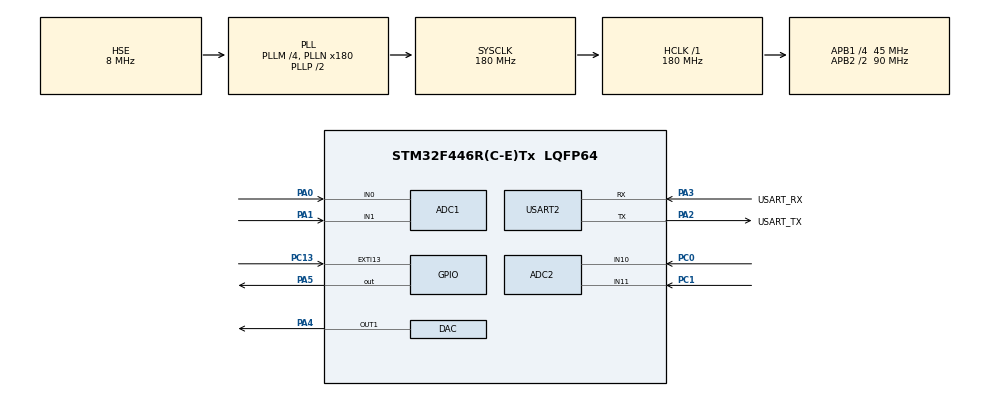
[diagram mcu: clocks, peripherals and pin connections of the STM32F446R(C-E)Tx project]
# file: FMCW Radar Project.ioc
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ADC1.Channel-0\#ChannelRegularConversion=ADC_CHANNEL_0
ADC1.Channel-1\#ChannelRegularConversion=ADC_CHANNEL_1
ADC1.DMAContinuousRequests=ENABLE
ADC1.ExternalTrigConv=ADC_EXTERNALTRIGCONV_T2_TRGO
ADC1.Mode=ADC_DUALMODE_REGSIMULT
ADC1.NbrOfConversion=2
ADC1.NbrOfConversionFlag=1
ADC1.Rank-0\#ChannelRegularConversion=1
ADC1.Rank-1\#ChannelRegularConversion=2
ADC1.SamplingTime-0\#ChannelRegularConversion=ADC_SAMPLETIME_28CYCLES
ADC1.SamplingTime-1\#ChannelRegularConversion=ADC_SAMPLETIME_28CYCLES
ADC1.ScanConvMode=ENABLE
ADC1.master=1
ADC2.Channel-2\#ChannelRegularConversion=ADC_CHANNEL_10
ADC2.Channel-3\#ChannelRegularConversion=ADC_CHANNEL_11
ADC2.DMAAccessMode=ADC_DMAACCESSMODE_2
ADC2.Mode=ADC_DUALMODE_REGSIMULT
ADC2.NbrOfConversion=2
ADC2.NbrOfConversionFlag=1
ADC2.Rank-2\#ChannelRegularConversion=1
ADC2.Rank-3\#ChannelRegularConversion=2
ADC2.SamplingTime-2\#ChannelRegularConversion=ADC_SAMPLETIME_28CYCLES
ADC2.SamplingTime-3\#ChannelRegularConversion=ADC_SAMPLETIME_28CYCLES
ADC2.ScanConvMode=ENABLE
DAC.DAC_Trigger=DAC_TRIGGER_T2_TRGO
Dma.ADC1.1.Direction=DMA_PERIPH_TO_MEMORY
Dma.ADC1.1.FIFOMode=DMA_FIFOMODE_DISABLE
Dma.ADC1.1.Instance=DMA2_Stream0
Dma.ADC1.1.MemDataAlignment=DMA_MDATAALIGN_WORD
Dma.ADC1.1.MemInc=DMA_MINC_ENABLE
Dma.ADC1.1.Mode=DMA_CIRCULAR
Dma.ADC1.1.PeriphDataAlignment=DMA_PDATAALIGN_WORD
Dma.ADC1.1.PeriphInc=DMA_PINC_DISABLE
Dma.ADC1.1.Priority=DMA_PRIORITY_LOW
Dma.DAC1.0.Direction=DMA_MEMORY_TO_PERIPH
Dma.DAC1.0.FIFOMode=DMA_FIFOMODE_DISABLE
Dma.DAC1.0.Instance=DMA1_Stream5
Dma.DAC1.0.MemDataAlignment=DMA_MDATAALIGN_HALFWORD
Dma.DAC1.0.MemInc=DMA_MINC_ENABLE
Dma.DAC1.0.Mode=DMA_CIRCULAR
Dma.DAC1.0.PeriphDataAlignment=DMA_PDATAALIGN_HALFWORD
Dma.DAC1.0.PeriphInc=DMA_PINC_DISABLE
Dma.DAC1.0.Priority=DMA_PRIORITY_LOW
Dma.Request0=DAC1
Dma.Request1=ADC1
IWDG.Prescaler=IWDG_PRESCALER_64
IWDG.Reload=249
Mcu.Family=STM32F4
Mcu.Name=STM32F446R(C-E)Tx
Mcu.Package=LQFP64
NUCLEO-F446RE.BUTTON=1
NUCLEO-F446RE.LD1=true
NVIC.DMA1_Stream5_IRQn=true\:0\:0\:false\:false\:true\:false\:true\:true
NVIC.DMA2_Stream0_IRQn=true\:0\:0\:false\:false\:true\:false\:true\:true
NVIC.EXTI15_10_IRQn=true\:0\:0\:false\:false\:true\:false\:true\:true
NVIC.PriorityGroup=NVIC_PRIORITYGROUP_0
NVIC.USART2_IRQn=true\:0\:0\:false\:false\:true\:true\:true\:true
PA0-WKUP.Signal=ADCx_IN0
PA1.Signal=ADCx_IN1
PA13.GPIO_Label=TMS
PA13.Mode=Serial_Wire
PA13.Signal=SYS_JTMS-SWDIO
PA14.GPIO_Label=TCK
PA14.Mode=Serial_Wire
PA14.Signal=SYS_JTCK-SWCLK
PA2.GPIO_Label=USART_TX
PA2.Mode=Asynchronous
PA2.Signal=USART2_TX
PA3.GPIO_Label=USART_RX
PA3.Mode=Asynchronous
PA3.Signal=USART2_RX
PA4.Signal=COMP_DAC1_group
PA5.Signal=GPIO_Output
PB3.GPIO_Label=SWO
PB3.Signal=SYS_JTDO-SWO
PC0.Signal=ADCx_IN10
PC1.Signal=ADCx_IN11
PC13.Signal=GPXTI13
PC14-OSC32_IN.Signal=RCC_OSC32_IN
PC15-OSC32_OUT.Signal=RCC_OSC32_OUT
PH0-OSC_IN.Mode=HSE-External-Clock-Source
PH0-OSC_IN.Signal=RCC_OSC_IN
PH1-OSC_OUT.Mode=HSE-External-Clock-Source
PH1-OSC_OUT.Signal=RCC_OSC_OUT
ProjectManager.HeapSize=0x200
ProjectManager.StackSize=0x400
ProjectManager.TargetToolchain=STM32CubeIDE
RCC.AHBFreq_Value=180000000
RCC.APB1CLKDivider=RCC_HCLK_DIV4
RCC.APB1Freq_Value=45000000
RCC.APB1TimFreq_Value=90000000
RCC.APB2CLKDivider=RCC_HCLK_DIV2
RCC.APB2Freq_Value=90000000
RCC.APB2TimFreq_Value=180000000
RCC.CortexFreq_Value=180000000
RCC.FLatency-AdvancedSettings=FLASH_LATENCY_5
RCC.HCLKFreq_Value=180000000
RCC.HSE_VALUE=8000000
RCC.HSI_VALUE=16000000
RCC.LSE_VALUE=32768
RCC.PLLM=4
RCC.PLLN=180
RCC.PLLSourceVirtual=RCC_PLLSOURCE_HSE
RCC.SYSCLKFreq_VALUE=180000000
RCC.SYSCLKSource=RCC_SYSCLKSOURCE_PLLCLK
RCC.USBFreq_Value=180000000
RCC.VCOOutputFreq_Value=360000000
SH.ADCx_IN0.0=ADC1_IN0,IN0
SH.ADCx_IN1.0=ADC1_IN1,IN1
SH.ADCx_IN10.0=ADC2_IN10,IN10
SH.ADCx_IN11.0=ADC2_IN11,IN11
SH.COMP_DAC1_group.0=DAC_OUT1,DAC_OUT1
TIM2.Period=1405
TIM2.TIM_MasterOutputTrigger=TIM_TRGO_UPDATE
USART2.VirtualMode=VM_ASYNC
VP_IWDG_VS_IWDG.Mode=IWDG_Activate
VP_NUCLEO-F446RE_VS_BSP_COMMON.Mode=COMMON
VP_TIM2_VS_ClockSourceINT.Mode=Internal
board=NUCLEO-F446RE

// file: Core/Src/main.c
/* USER CODE BEGIN Header */
/**
  ******************************************************************************
  * @file           : main.c
  * @brief          : Main program body
  ******************************************************************************
  * @attention
  *
  * Copyright (c) 2026 STMicroelectronics.
  * All rights reserved.
  *
  * This software is licensed under terms that can be found in the LICENSE file
  * in the root directory of this software component.
  * If no LICENSE file comes with this software, it is provided AS-IS.
  *
  ******************************************************************************
  */
/* USER CODE END Header */
#include "main.h"

/* USER CODE BEGIN Includes */
/* USER CODE BEGIN Includes */
#include "radar.h"
/* USER CODE END Includes */
/* USER CODE END Includes */

ADC_HandleTypeDef hadc1;
ADC_HandleTypeDef hadc2;
DMA_HandleTypeDef hdma_adc1;

DAC_HandleTypeDef hdac;
DMA_HandleTypeDef hdma_dac1;

IWDG_HandleTypeDef hiwdg;

TIM_HandleTypeDef htim2;

UART_HandleTypeDef huart2;

void SystemClock_Config(void);
static void MX_GPIO_Init(void);
static void MX_DMA_Init(void);
static void MX_USART2_UART_Init(void);
static void MX_DAC_Init(void);
static void MX_TIM2_Init(void);
static void MX_ADC1_Init(void);
static void MX_ADC2_Init(void);
static void MX_IWDG_Init(void);

int main(void)
{

  /* MCU Configuration--------------------------------------------------------*/

  /* Reset of all peripherals, Initializes the Flash interface and the Systick. */
  HAL_Init();

  /* Configure the system clock */
  SystemClock_Config();

  /* Initialize all configured peripherals */
  MX_GPIO_Init();
  MX_DMA_Init();
  MX_USART2_UART_Init();
  MX_DAC_Init();
  MX_TIM2_Init();
  MX_ADC1_Init();
  MX_ADC2_Init();
  MX_IWDG_Init();
  /* USER CODE BEGIN 2 */
  /* USER CODE BEGIN 2 */
  radar_start();
  /* USER CODE END 2 */
  /* USER CODE END 2 */

  /* Initialize leds */
  BSP_LED_Init(LED2);

  /* Initialize USER push-button, will be used to trigger an interrupt each time it's pressed.*/
  BSP_PB_Init(BUTTON_USER, BUTTON_MODE_EXTI);

  /* Infinite loop */
  while (1)
  {

    /* USER CODE BEGIN 3 */
	  /* USER CODE BEGIN 3 */
	  radar_loop();
	}
	/* USER CODE END 3 */
  /* USER CODE END 3 */
}

void SystemClock_Config(void)
{
  RCC_OscInitTypeDef RCC_OscInitStruct = {0};
  RCC_ClkInitTypeDef RCC_ClkInitStruct = {0};

  /** Configure the main internal regulator output voltage
  */
  __HAL_RCC_PWR_CLK_ENABLE();
  __HAL_PWR_VOLTAGESCALING_CONFIG(PWR_REGULATOR_VOLTAGE_SCALE1);

  /** Initializes the RCC Oscillators according to the specified parameters
  * in the RCC_OscInitTypeDef structure.
  */
  RCC_OscInitStruct.OscillatorType = RCC_OSCILLATORTYPE_LSI|RCC_OSCILLATORTYPE_HSE;
  RCC_OscInitStruct.HSEState = RCC_HSE_BYPASS;
  RCC_OscInitStruct.LSIState = RCC_LSI_ON;
  RCC_OscInitStruct.PLL.PLLState = RCC_PLL_ON;
  RCC_OscInitStruct.PLL.PLLSource = RCC_PLLSOURCE_HSE;
  RCC_OscInitStruct.PLL.PLLM = 4;
  RCC_OscInitStruct.PLL.PLLN = 180;
  RCC_OscInitStruct.PLL.PLLP = RCC_PLLP_DIV2;
  RCC_OscInitStruct.PLL.PLLQ = 2;
  RCC_OscInitStruct.PLL.PLLR = 2;
  if (HAL_RCC_OscConfig(&RCC_OscInitStruct) != HAL_OK)
  {
    Error_Handler();
  }

  /** Activate the Over-Drive mode
  */
  if (HAL_PWREx_EnableOverDrive() != HAL_OK)
  {
    Error_Handler();
  }

  /** Initializes the CPU, AHB and APB buses clocks
  */
  RCC_ClkInitStruct.ClockType = RCC_CLOCKTYPE_HCLK|RCC_CLOCKTYPE_SYSCLK
                              |RCC_CLOCKTYPE_PCLK1|RCC_CLOCKTYPE_PCLK2;
  RCC_ClkInitStruct.SYSCLKSource = RCC_SYSCLKSOURCE_PLLCLK;
  RCC_ClkInitStruct.AHBCLKDivider = RCC_SYSCLK_DIV1;
  RCC_ClkInitStruct.APB1CLKDivider = RCC_HCLK_DIV4;
  RCC_ClkInitStruct.APB2CLKDivider = RCC_HCLK_DIV2;

  if (HAL_RCC_ClockConfig(&RCC_ClkInitStruct, FLASH_LATENCY_5) != HAL_OK)
  {
    Error_Handler();
  }
}

static void MX_ADC1_Init(void)
{

  ADC_MultiModeTypeDef multimode = {0};
  ADC_ChannelConfTypeDef sConfig = {0};

  /** Configure the global features of the ADC (Clock, Resolution, Data Alignment and number of conversion)
  */
  hadc1.Instance = ADC1;
  hadc1.Init.ClockPrescaler = ADC_CLOCK_SYNC_PCLK_DIV4;
  hadc1.Init.Resolution = ADC_RESOLUTION_12B;
  hadc1.Init.ScanConvMode = ENABLE;
  hadc1.Init.ContinuousConvMode = DISABLE;
  hadc1.Init.DiscontinuousConvMode = DISABLE;
  hadc1.Init.ExternalTrigConvEdge = ADC_EXTERNALTRIGCONVEDGE_RISING;
  hadc1.Init.ExternalTrigConv = ADC_EXTERNALTRIGCONV_T2_TRGO;
  hadc1.Init.DataAlign = ADC_DATAALIGN_RIGHT;
  hadc1.Init.NbrOfConversion = 2;
  hadc1.Init.DMAContinuousRequests = ENABLE;
  hadc1.Init.EOCSelection = ADC_EOC_SINGLE_CONV;
  if (HAL_ADC_Init(&hadc1) != HAL_OK)
  {
    Error_Handler();
  }

  /** Configure the ADC multi-mode
  */
  multimode.Mode = ADC_DUALMODE_REGSIMULT;
  multimode.DMAAccessMode = ADC_DMAACCESSMODE_2;
  multimode.TwoSamplingDelay = ADC_TWOSAMPLINGDELAY_5CYCLES;
  if (HAL_ADCEx_MultiModeConfigChannel(&hadc1, &multimode) != HAL_OK)
  {
    Error_Handler();
  }

  /** Configure for the selected ADC regular channel its corresponding rank in the sequencer and its sample time.
  */
  sConfig.Channel = ADC_CHANNEL_0;
  sConfig.Rank = 1;
  sConfig.SamplingTime = ADC_SAMPLETIME_28CYCLES;
  if (HAL_ADC_ConfigChannel(&hadc1, &sConfig) != HAL_OK)
  {
    Error_Handler();
  }

  /** Configure for the selected ADC regular channel its corresponding rank in the sequencer and its sample time.
  */
  sConfig.Channel = ADC_CHANNEL_1;
  sConfig.Rank = 2;
  if (HAL_ADC_ConfigChannel(&hadc1, &sConfig) != HAL_OK)
  {
    Error_Handler();
  }

}

static void MX_ADC2_Init(void)
{

  ADC_ChannelConfTypeDef sConfig = {0};

  /** Configure the global features of the ADC (Clock, Resolution, Data Alignment and number of conversion)
  */
  hadc2.Instance = ADC2;
  hadc2.Init.ClockPrescaler = ADC_CLOCK_SYNC_PCLK_DIV4;
  hadc2.Init.Resolution = ADC_RESOLUTION_12B;
  hadc2.Init.ScanConvMode = ENABLE;
  hadc2.Init.ContinuousConvMode = DISABLE;
  hadc2.Init.DiscontinuousConvMode = DISABLE;
  hadc2.Init.DataAlign = ADC_DATAALIGN_RIGHT;
  hadc2.Init.NbrOfConversion = 2;
  hadc2.Init.DMAContinuousRequests = DISABLE;
  hadc2.Init.EOCSelection = ADC_EOC_SINGLE_CONV;
  if (HAL_ADC_Init(&hadc2) != HAL_OK)
  {
    Error_Handler();
  }

  /** Configure for the selected ADC regular channel its corresponding rank in the sequencer and its sample time.
  */
  sConfig.Channel = ADC_CHANNEL_10;
  sConfig.Rank = 1;
  sConfig.SamplingTime = ADC_SAMPLETIME_28CYCLES;
  if (HAL_ADC_ConfigChannel(&hadc2, &sConfig) != HAL_OK)
  {
    Error_Handler();
  }

  /** Configure for the selected ADC regular channel its corresponding rank in the sequencer and its sample time.
  */
  sConfig.Channel = ADC_CHANNEL_11;
  sConfig.Rank = 2;
  if (HAL_ADC_ConfigChannel(&hadc2, &sConfig) != HAL_OK)
  {
    Error_Handler();
  }

}

static void MX_DAC_Init(void)
{

  DAC_ChannelConfTypeDef sConfig = {0};

  /** DAC Initialization
  */
  hdac.Instance = DAC;
  if (HAL_DAC_Init(&hdac) != HAL_OK)
  {
    Error_Handler();
  }

  /** DAC channel OUT1 config
  */
  sConfig.DAC_Trigger = DAC_TRIGGER_T2_TRGO;
  sConfig.DAC_OutputBuffer = DAC_OUTPUTBUFFER_ENABLE;
  if (HAL_DAC_ConfigChannel(&hdac, &sConfig, DAC_CHANNEL_1) != HAL_OK)
  {
    Error_Handler();
  }

}

static void MX_IWDG_Init(void)
{

  hiwdg.Instance = IWDG;
  hiwdg.Init.Prescaler = IWDG_PRESCALER_64;
  hiwdg.Init.Reload = 249;
  if (HAL_IWDG_Init(&hiwdg) != HAL_OK)
  {
    Error_Handler();
  }

}

static void MX_TIM2_Init(void)
{

  TIM_ClockConfigTypeDef sClockSourceConfig = {0};
  TIM_MasterConfigTypeDef sMasterConfig = {0};

  htim2.Instance = TIM2;
  htim2.Init.Prescaler = 0;
  htim2.Init.CounterMode = TIM_COUNTERMODE_UP;
  htim2.Init.Period = 1405;
  htim2.Init.ClockDivision = TIM_CLOCKDIVISION_DIV1;
  htim2.Init.AutoReloadPreload = TIM_AUTORELOAD_PRELOAD_DISABLE;
  if (HAL_TIM_Base_Init(&htim2) != HAL_OK)
  {
    Error_Handler();
  }
  sClockSourceConfig.ClockSource = TIM_CLOCKSOURCE_INTERNAL;
  if (HAL_TIM_ConfigClockSource(&htim2, &sClockSourceConfig) != HAL_OK)
  {
    Error_Handler();
  }
  sMasterConfig.MasterOutputTrigger = TIM_TRGO_UPDATE;
  sMasterConfig.MasterSlaveMode = TIM_MASTERSLAVEMODE_DISABLE;
  if (HAL_TIMEx_MasterConfigSynchronization(&htim2, &sMasterConfig) != HAL_OK)
  {
    Error_Handler();
  }

}

static void MX_USART2_UART_Init(void)
{

  huart2.Instance = USART2;
  huart2.Init.BaudRate = 115200;
  huart2.Init.WordLength = UART_WORDLENGTH_8B;
  huart2.Init.StopBits = UART_STOPBITS_1;
  huart2.Init.Parity = UART_PARITY_NONE;
  huart2.Init.Mode = UART_MODE_TX_RX;
  huart2.Init.HwFlowCtl = UART_HWCONTROL_NONE;
  huart2.Init.OverSampling = UART_OVERSAMPLING_16;
  if (HAL_UART_Init(&huart2) != HAL_OK)
  {
    Error_Handler();
  }

}

static void MX_DMA_Init(void)
{

  /* DMA controller clock enable */
  __HAL_RCC_DMA1_CLK_ENABLE();
  __HAL_RCC_DMA2_CLK_ENABLE();

  /* DMA interrupt init */
  /* DMA1_Stream5_IRQn interrupt configuration */
  HAL_NVIC_SetPriority(DMA1_Stream5_IRQn, 0, 0);
  HAL_NVIC_EnableIRQ(DMA1_Stream5_IRQn);
  /* DMA2_Stream0_IRQn interrupt configuration */
  HAL_NVIC_SetPriority(DMA2_Stream0_IRQn, 0, 0);
  HAL_NVIC_EnableIRQ(DMA2_Stream0_IRQn);

}

static void MX_GPIO_Init(void)
{

  /* GPIO Ports Clock Enable */
  __HAL_RCC_GPIOC_CLK_ENABLE();
  __HAL_RCC_GPIOH_CLK_ENABLE();
  __HAL_RCC_GPIOA_CLK_ENABLE();
  __HAL_RCC_GPIOB_CLK_ENABLE();

}

void Error_Handler(void)
{
  __disable_irq();
  while (1)
  {
  }
}
